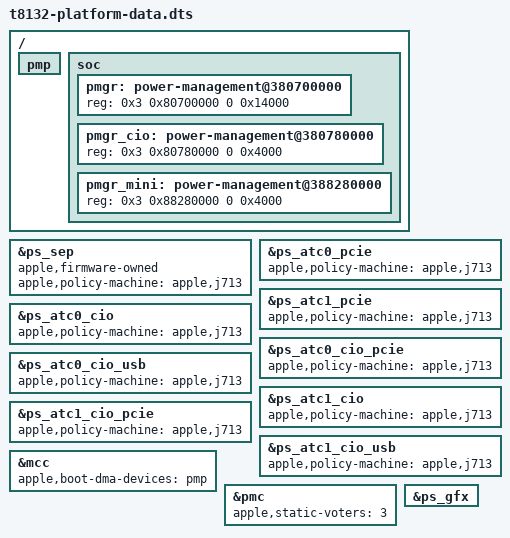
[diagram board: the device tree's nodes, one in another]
// SPDX-License-Identifier: GPL-2.0+ OR MIT
/dts-v1/;

/* Reference placeholders are replaced with the live provider phandles. */
/ {
	#address-cells = <2>;
	#size-cells = <2>;
	pmp: pmp { phandle = <1>; };
	soc: soc {
		#address-cells = <2>;
		#size-cells = <2>;
		ranges;

		pmgr: power-management@380700000 {
			#address-cells = <1>;
			#size-cells = <1>;
			reg = <0x3 0x80700000 0 0x14000>;
		};

		/* Describes no domain; resolves the CIO PMGR the SoC tree carries. */
		pmgr_cio: power-management@380780000 {
			#address-cells = <1>;
			#size-cells = <1>;
			reg = <0x3 0x80780000 0 0x4000>;
		};

		pmgr_mini: power-management@388280000 {
			#address-cells = <1>;
			#size-cells = <1>;
			reg = <0x3 0x88280000 0 0x4000>;
		};
	};
};

#include "../../../arch/arm64/boot/dts/apple/t8132-pmgr.dtsi"
#include "../../../arch/arm64/boot/dts/apple/t8132-j713-pmgr.dtsi"
#include "../../../arch/arm64/boot/dts/apple/t8132-j713-usb4-pmgr.dtsi"
#include "../../../arch/arm64/boot/dts/apple/t8132-memory.dtsi"

/* The J713's SEP domain, for its deep sleep: every other board keeps it off. */
&ps_sep {
	apple,firmware-owned;
	status = "okay";
	apple,policy-machine = "apple,j713";
};

/* The J713's ACIO power states: every other board keeps its own (or none). */
&ps_atc0_pcie {
	apple,policy-machine = "apple,j713";
};

&ps_atc1_pcie {
	apple,policy-machine = "apple,j713";
};

&ps_atc0_cio {
	apple,policy-machine = "apple,j713";
};

&ps_atc0_cio_pcie {
	apple,policy-machine = "apple,j713";
};

&ps_atc0_cio_usb {
	apple,policy-machine = "apple,j713";
};

&ps_atc1_cio {
	apple,policy-machine = "apple,j713";
};

&ps_atc1_cio_pcie {
	apple,policy-machine = "apple,j713";
};

&ps_atc1_cio_usb {
	apple,policy-machine = "apple,j713";
};

&mcc {
	apple,boot-dma-devices = <&pmp>;
};

&pmc {
	apple,static-voters = <3>;
};

/*
 * The PMC interface domains' parents are PMGR states, which a copied phandle
 * cannot reach in the loader's tree, and no loader PMGR state uses them.
 */
/delete-node/ &pmc_dispext0;
/delete-node/ &pmc_dispext1;

&ps_gfx {
	status = "okay";
};
